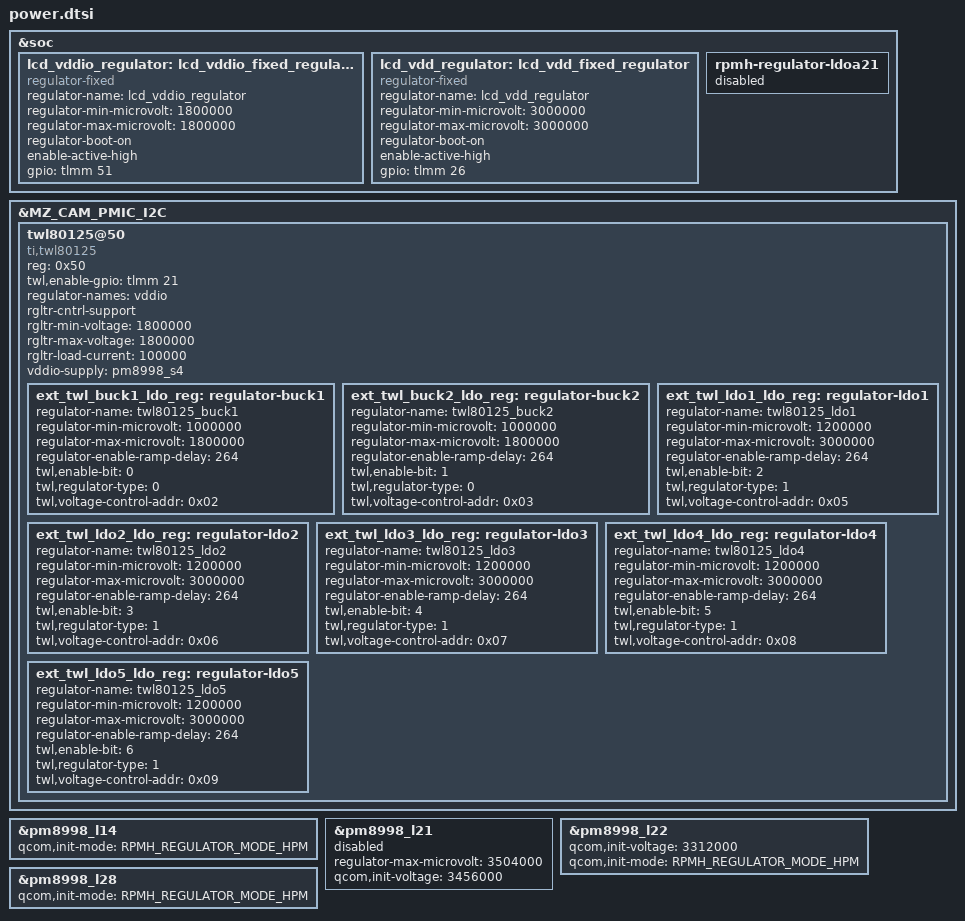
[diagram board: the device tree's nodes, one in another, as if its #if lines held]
/*
 * Copyright (c) 2024, MeizuCustoms enthusiasts
 *
 * This program is free software; you can redistribute it and/or modify
 * it under the terms of the GNU General Public License version 2 and
 * only version 2 as published by the Free Software Foundation.
 *
 * This program is distributed in the hope that it will be useful,
 * but WITHOUT ANY WARRANTY; without even the implied warranty of
 * MERCHANTABILITY or FITNESS FOR A PARTICULAR PURPOSE.  See the
 * GNU General Public License for more details.
 */

#include <dt-bindings/regulator/qcom,rpmh-regulator.h>

&soc {
	lcd_vddio_regulator: lcd_vddio_fixed_regulator {
		compatible = "regulator-fixed";
		regulator-name = "lcd_vddio_regulator";
		regulator-min-microvolt = <1800000>;
		regulator-max-microvolt = <1800000>;
		regulator-boot-on;
		enable-active-high;

		gpio = <&tlmm 51 0x0>;
	};

	lcd_vdd_regulator: lcd_vdd_fixed_regulator {
		compatible = "regulator-fixed";
		regulator-name = "lcd_vdd_regulator";
		regulator-min-microvolt = <3000000>;
		regulator-max-microvolt = <3000000>;
		regulator-boot-on;
		enable-active-high;

		gpio = <&tlmm 26 0x0>;
	};

    rpmh-regulator-ldoa21 {
        status = "disabled";
    };
};

/* Camera PMIC bus: QUP SE14 on m1882, QUP SE4 (i2c@890000) on m1892 */
#ifdef MZ_M1892
#define MZ_CAM_PMIC_I2C qupv3_se4_i2c
#else
#define MZ_CAM_PMIC_I2C qupv3_se14_i2c
#endif

&MZ_CAM_PMIC_I2C {
    status = "ok";

    twl80125@50 {
        compatible = "ti,twl80125";
        reg = <0x50>;

        twl,enable-gpio = <&tlmm 21 0x0>;

        regulator-names = "vddio";
        rgltr-cntrl-support;
        rgltr-min-voltage = <1800000>;
        rgltr-max-voltage = <1800000>;
        rgltr-load-current = <100000>;

        vddio-supply = <&pm8998_s4>;

        ext_twl_buck1_ldo_reg: regulator-buck1 {
            regulator-name = "twl80125_buck1";
            regulator-min-microvolt = <1000000>;
            regulator-max-microvolt = <1800000>;
            regulator-enable-ramp-delay = <264>;

            twl,enable-bit = <0>;
            twl,regulator-type = <0>;
            twl,voltage-control-addr = <0x02>;
        };

        ext_twl_buck2_ldo_reg: regulator-buck2 {
            regulator-name = "twl80125_buck2";
            regulator-min-microvolt = <1000000>;
            regulator-max-microvolt = <1800000>;
            regulator-enable-ramp-delay = <264>;    

            twl,enable-bit = <1>;
            twl,regulator-type = <0>;
            twl,voltage-control-addr = <0x03>;
        };

        ext_twl_ldo1_ldo_reg: regulator-ldo1 {
            regulator-name = "twl80125_ldo1";
            regulator-min-microvolt = <1200000>;
            regulator-max-microvolt = <3000000>;
            regulator-enable-ramp-delay = <264>;

            twl,enable-bit = <2>;
            twl,regulator-type = <1>;
            twl,voltage-control-addr = <0x05>;
        };

        ext_twl_ldo2_ldo_reg: regulator-ldo2 {
            regulator-name = "twl80125_ldo2";
            regulator-min-microvolt = <1200000>;
            regulator-max-microvolt = <3000000>;
            regulator-enable-ramp-delay = <264>;

            twl,enable-bit = <3>;
            twl,regulator-type = <1>;
            twl,voltage-control-addr = <0x06>;
        };

        ext_twl_ldo3_ldo_reg: regulator-ldo3 {
            regulator-name = "twl80125_ldo3";
            regulator-min-microvolt = <1200000>;
            regulator-max-microvolt = <3000000>;
            regulator-enable-ramp-delay = <264>;
            
            twl,enable-bit = <4>;
            twl,regulator-type = <1>;
            twl,voltage-control-addr = <0x07>;
        };

        ext_twl_ldo4_ldo_reg: regulator-ldo4 {
            regulator-name = "twl80125_ldo4";
            regulator-min-microvolt = <1200000>;
            regulator-max-microvolt = <3000000>;
            regulator-enable-ramp-delay = <264>;

            twl,enable-bit = <5>;
            twl,regulator-type = <1>;
            twl,voltage-control-addr = <0x08>;
        };

        ext_twl_ldo5_ldo_reg: regulator-ldo5 {
            regulator-name = "twl80125_ldo5";
            regulator-min-microvolt = <1200000>;
            regulator-max-microvolt = <3000000>;
            regulator-enable-ramp-delay = <264>;

            twl,enable-bit = <6>;
            twl,regulator-type = <1>;
            twl,voltage-control-addr = <0x09>;
        };
    };
};

&pm8998_l14 {
    qcom,init-mode = <RPMH_REGULATOR_MODE_HPM>;
};

&pm8998_l21 {
    regulator-max-microvolt = <3504000>;
	qcom,init-voltage = <3456000>;
    status = "disabled";
};

&pm8998_l22 {
    qcom,init-voltage = <3312000>;
    qcom,init-mode = <RPMH_REGULATOR_MODE_HPM>;
};

&pm8998_l28 {
    qcom,init-mode = <RPMH_REGULATOR_MODE_HPM>;
};
